# STM32MP21_CA35 register map
File version: 0.4
CPU: CM33 r0p1, little endian, MPU, FPU, vendor SysTick, 8 interrupt priority bits
Registers are 32-bit, read-write, reset 0x0 unless marked. A register's access mark holds for its fields unless they carry their own. Offsets are from the block's base; [hi:lo] are bit positions; 'fields as' and 'values as' point back to an identical list.

## TIM10 — TIM10 address block description
Base 0x401C0000
Same registers: TIM10_S 0x501C0000
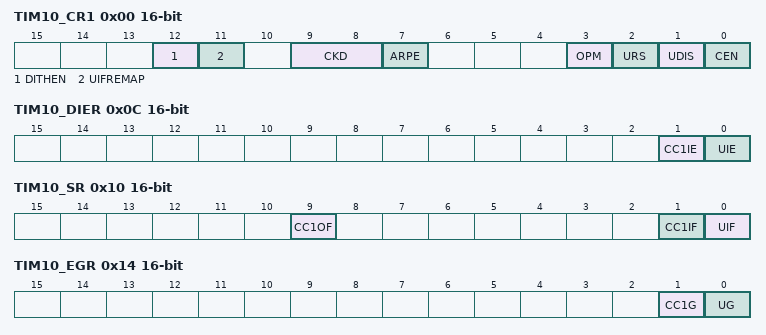
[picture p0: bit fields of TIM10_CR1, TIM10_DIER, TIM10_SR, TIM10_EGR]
0x00 TIM10_CR1 16-bit — TIM10 control register 1
  [12] DITHEN — Dithering enable
    0=Dithering disabled; 1=Dithering enabled
  [11] UIFREMAP — UIF status bit remapping
    0=No remapping; 1=Remapping enabled
  [9:8] CKD — Clock division
    0=tless thansub>DTSless than/sub> = tless thansub>tim_ker_ckless than/sub>; 1=tless thansub>DTSless than/sub> = 2 x tless thansub>tim_ker_ckless than/sub>; 2=tless thansub>DTSless than/sub> = 4 x tless thansub>tim_ker_ckless than/sub>
  [7] ARPE — Auto-reload preload enable
    0=TIMx_ARR register is not buffered; 1=TIMx_ARR register is buffered
  [3] OPM — One-pulse mode
    0=Counter is not stopped on the update event; 1=Counter stops counting on the next update event (clearing the CEN bit)
  [2] URS — Update request source
    0=Any of the following events generate an UEV if enabled:; 1=Only counter overflow generates an UEV if enabled
  [1] UDIS — Update disable
    0=UEV enabled; 1=UEV disabled
  [0] CEN — Counter enable
    0=Counter disabled; 1=Counter enabled
0x0C TIM10_DIER 16-bit — TIM10 Interrupt enable register
  [1] CC1IE — Capture/Compare 1 interrupt enable
    0=CC1 interrupt disabled; 1=CC1 interrupt enabled
  [0] UIE — Update interrupt enable
    0=Update interrupt disabled; 1=Update interrupt enabled
0x10 TIM10_SR 16-bit — TIM10 status register
  [9] CC1OF — Capture/Compare 1 overcapture flag
    0=No overcapture has been detected; 1=The counter value has been captured in TIMx_CCR1 register while CC1IF flag was already set
  [1] CC1IF — Capture/compare 1 interrupt flag
    0=No compare match / No input capture occurred; 1=A compare match or an input capture occurred
  [0] UIF — Update interrupt flag
    0=No update occurred; 1=Update interrupt pending
0x14 TIM10_EGR 16-bit wo — TIM10 event generation register
  [1] CC1G — Capture/compare 1 generation
    0=No action; 1=A capture/compare event is generated on channel 1:
  [0] UG — Update generation
    0=No action; 1=Re-initialize the counter and generates an update of the registers
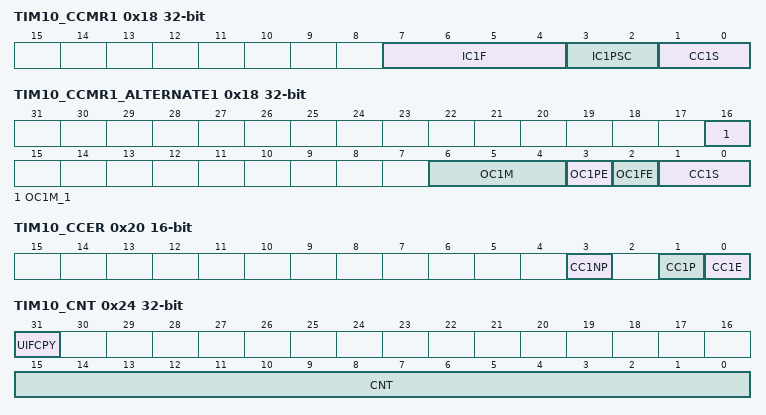
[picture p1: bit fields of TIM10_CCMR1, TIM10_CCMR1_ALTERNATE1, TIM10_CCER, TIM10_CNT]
0x18 TIM10_CCMR1 — TIM10 capture/compare mode register 1
  [7:4] IC1F — Input capture 1 filter
    0=No filter, sampling is done at fless thansub>DTSless than/sub>; 1=fless thansub>SAMPLINGless than/sub>=fless thansub>tim_ker_ckless than/sub>, N=2; 2=fless thansub>SAMPLINGless than/sub>=fless thansub>tim_ker_ckless than/sub>, N=4; 3=fless thansub>SAMPLINGless than/sub>=fless thansub>tim_ker_ckless than/sub>, N=8; 4=fless thansub>SAMPLINGless than/sub>=fless thansub>DTSless than/sub>/2, N=6; 5=fless thansub>SAMPLINGless than/sub>=fless thansub>DTSless than/sub>/2, N=8; 6=fless thansub>SAMPLINGless than/sub>=fless thansub>DTSless than/sub>/4, N=6; 7=fless thansub>SAMPLINGless than/sub>=fless thansub>DTSless than/sub>/4, N=8; 8=fless thansub>SAMPLINGless than/sub>=fless thansub>DTSless than/sub>/8, N=6; 9=fless thansub>SAMPLINGless than/sub>=fless thansub>DTSless than/sub>/8, N=8; 10=fless thansub>SAMPLINGless than/sub>=fless thansub>DTSless than/sub>/16, N=5; 11=fless thansub>SAMPLINGless than/sub>=fless thansub>DTSless than/sub>/16, N=6; 12=fless thansub>SAMPLINGless than/sub>=fless thansub>DTSless than/sub>/16, N=8; 13=fless thansub>SAMPLINGless than/sub>=fless thansub>DTSless than/sub>/32, N=5; 14=fless thansub>SAMPLINGless than/sub>=fless thansub>DTSless than/sub>/32, N=6; 15=fless thansub>SAMPLINGless than/sub>=fless thansub>DTSless than/sub>/32, N=8
  [3:2] IC1PSC — Input capture 1 prescaler
    0=no prescaler, capture is done each time an edge is detected on the capture input; 1=capture is done once every 2 events; 2=capture is done once every 4 events; 3=capture is done once every 8 events
  [1:0] CC1S — Capture/Compare 1 selection
    0=CC1 channel is configured as output; 1=CC1 channel is configured as input, tim_ic1 is mapped on tim_ti1
0x18 TIM10_CCMR1_ALTERNATE1 (alternate view of TIM10_CCMR1) — TIM10 capture/compare mode register 1
  [16] OC1M_1 — OC1M[3]
  [6:4] OC1M — OC1M[2:0]: Output compare 1 mode (refer to bit 16 for OC1M[3])
    0=Frozen; 1=Set channel 1 to active level on match; 2=Set channel 1 to inactive level on match; 3=Toggle - tim_oc1ref toggles when TIMx_CNT = TIMx_CCR1; 4=Force inactive level - tim_oc1ref is forced low; 5=Force active level - tim_oc1ref is forced high; 6=PWM mode 1 - Channel 1 is active as long as TIMx_CNT less than TIMx_CCR1 else inactive; 7=PWM mode 2 - Channel 1 is inactive as long as TIMx_CNT less than TIMx_CCR1 else active
  [3] OC1PE — Output compare 1 preload enable
    0=Preload register on TIMx_CCR1 disabled; 1=Preload register on TIMx_CCR1 enabled
  [2] OC1FE — Output compare 1 fast enable
    0=CC1 behaves normally depending on counter and CCR1 values even when the trigger is ON; 1=An active edge on the trigger input acts like a compare match on CC1 output
  [1:0] CC1S — Capture/Compare 1 selection
    values as TIM10_CCMR1.CC1S
0x20 TIM10_CCER 16-bit — TIM10 capture/compare enable register
  [3] CC1NP — Capture/Compare 1 complementary output Polarity.
  [1] CC1P — Capture/Compare 1 output Polarity.
    0=tim_oc1 active high (output mode) / Edge sensitivity selection (input mode, see below); 1=tim_oc1 active low (output mode) / Edge sensitivity selection (input mode, see below)
  [0] CC1E — Capture/Compare 1 output enable.
    0=Capture mode disabled / tim_oc1 is not active; 1=Capture mode enabled / tim_oc1 signal is output on the corresponding output pin
0x24 TIM10_CNT — TIM10 counter
  [31] UIFCPY — UIF Copy
  [15:0] CNT — Counter value
0x28 TIM10_PSC 16-bit — TIM10 prescaler
  [15:0] PSC — Prescaler value
0x2C TIM10_ARR reset 0xFFFF — TIM10 auto-reload register
  [19:0] ARR — Auto-reload value
0x34 TIM10_CCR1 — TIM10 capture/compare register 1
  [19:0] CCR1 — Capture/compare 1 value
0x5C TIM10_TISEL 16-bit — TIM10 timer input selection register
  [3:0] TI1SEL — selects tim_ti1_in[15:0] input
    0=TIMx_CH1 input (tim_ti1_in0); 1=tim_ti1_in1; 15=tim_ti1_in15
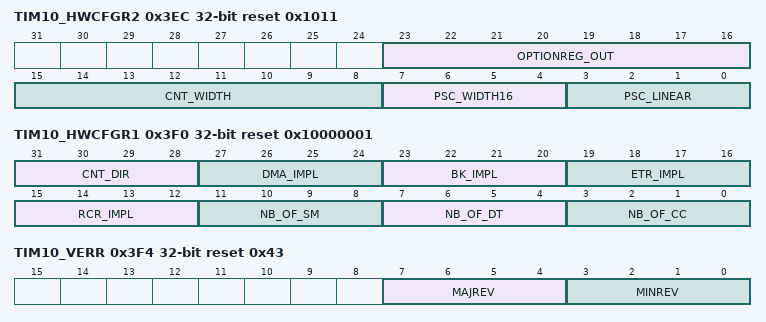
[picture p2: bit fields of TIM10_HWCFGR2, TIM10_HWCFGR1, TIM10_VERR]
0x3EC TIM10_HWCFGR2 ro reset 0x1011 — TIM10 hardware configuration 2 register
  [23:16] OPTIONREG_OUT — Option register number (0 to 16).
  [15:8] CNT_WIDTH — Counter width
    8=8-bits; 16=16-bits; 32=32-bits
  [7:4] PSC_WIDTH16 — Prescaler width
    0=7 (by power of 2) /8 (linear) -bit counter; 1=15 (by power of 2) /16 (linear) -bit counter
  [3:0] PSC_LINEAR — Prescaler linear
    0=prescaler by power of 2 (division by 1, 2, 4, 8; 1=prescaler is linear (division by 1, 2, 3, 4, 5
0x3F0 TIM10_HWCFGR1 ro reset 0x10000001 — TIM10 hardware configuration 1 register
  [31:28] CNT_DIR — Counter direction
    0=Down-counter only; 1=Up-counter only; 2=Up/Down counter allowing center-aligned mode
  [27:24] DMA_IMPL — DMA features implementation
    0=DMA requests are not possible; 1=Single DMA requests possible; 2=All DMA features implemented
  [23:20] BK_IMPL — Break circuit implementation
    0=no break implemented; 1=break1 implemented without filter (tim_brk + tim_sys_brk connected); 2=break1 implemented with filter (tim_brk + tim_sys_brk connected); 3=break 1 and 2 implemented (tim_brk + tim_sys_brk + brk2)
  [19:16] ETR_IMPL — External trigger implementation
    0=External trigger circuit not implemented, ocrefx cleared by ocref_clr input; 1=External trigger circuit implemented, ocrefx cleared by ocref_clr input; 2=External trigger circuit implemented, ocrefx cleared by etrf signal; 3=External trigger circuit implemented, ocrefx cleared by ocref_clr or etrf (1 control bit OCCS added in GPT_SMCR)
  [15:12] RCR_IMPL — Repetition counter implementation
    0=repetition counter not implemented; 1=8-bit repetition counter implemented; 2=16-bit repetition counter implemented
  [11:8] NB_OF_SM — Number of synchronization module
    0=synchronization module not implemented; 1=1 synchronization module implemented
  [7:4] NB_OF_DT — Number of complementary outputs and dead-time generators
  [3:0] NB_OF_CC — Number of capture / compare channel
    0=no capture/compare channel implemented; 1=only CC1 channel is implemented; 2=CC1 and CC2 channels are implemented; 3=CC1, CC2 and CC3 channels are implemented; 4=CC1, CC2, CC3 and CC4 channels are implemented; 5=CC1, CC2, CC3, CC4 and CC5 channels are implemented; 6=CC1, CC2, CC3, CC4, CC5 and CC6 channels are implemented
0x3F4 TIM10_VERR ro reset 0x43 — TIM10 IP version register
  [7:4] MAJREV — Major revision number.
  [3:0] MINREV — Minor revision number.
0x3F8 TIM10_IPIDR ro reset 0x120002 — TIM10 IP identification register
  [31:0] ID — IP identification code.
0x3FC TIM10_SIDR ro reset 0xA3C5DD01 — TIM10 size ID register
  [31:0] SID — Offset in KB of the ID register base address from the IP base address.
    1=1KB offset

## TIM11 — TIM11 address block description
Base 0x401D0000
Same registers: TIM11_S 0x501D0000
Registers as TIM10 (with TIM10 read as TIM11).

## TIM13 — TIM13 address block description
Base 0x40070000
Same registers: TIM13_S 0x50070000
Registers as TIM10 (with TIM10 read as TIM13).

## TIM14 — TIM14 address block description
Base 0x40080000
Same registers: TIM14_S 0x50080000
Registers as TIM10 (with TIM10 read as TIM14).
